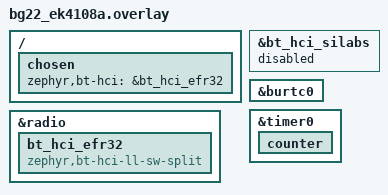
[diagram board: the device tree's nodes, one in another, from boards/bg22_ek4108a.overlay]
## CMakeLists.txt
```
cmake_minimum_required(VERSION 3.20.0)
# Compile test for modules/efr32-radio: Zephyr's own split controller on the EFR32BG22.
# UNVALIDATED ON HARDWARE; the radio hooks are stubs. Build with:
#   west build -b bg22_ek4108a tests/radio-port -- -DZEPHYR_EXTRA_MODULES=<repo>/modules/efr32-radio
if(NOT DEFINED ZEPHYR_RUST_MODULE)
  set(ZEPHYR_RUST_MODULE ${CMAKE_CURRENT_LIST_DIR}/../../vendor/zephyr-lang-rust)
endif()
list(APPEND ZEPHYR_EXTRA_MODULES
    ${CMAKE_CURRENT_LIST_DIR}/../../modules/efr32-radio
    ${ZEPHYR_RUST_MODULE})
find_package(Zephyr REQUIRED HINTS $ENV{ZEPHYR_BASE})
project(efr32_radio_port)
rust_cargo_application()
target_sources(app PRIVATE src/adv.c)
if(CONFIG_RADIO_PORT_GATT_TEST)
  target_sources(app PRIVATE src/gatt.c)
endif()
```

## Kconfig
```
# Test-only configuration for the EFR32 radio-port advertiser.

menu "EFR32 radio-port test"

config RADIO_PORT_GATT_TEST
	bool "Serve a read/write test characteristic to the QEMU Central"
	depends on BT_PERIPHERAL
	default n
	help
	  One 4-octet characteristic (src/gatt.c) that the QEMU connection
	  workload's Central writes and reads back to check the link end to
	  end. QEMU connection profile only.

config RADIO_PORT_PAIRING_TEST
	bool "Require LE Secure Connections pairing with a passkey for the test characteristic"
	depends on RADIO_PORT_GATT_TEST && BT_SMP && BT_APP_PASSKEY
	help
	  The characteristic needs an authenticated (MITM) encrypted link, as the product's do,
	  and the passkey is RADIO_PORT_PASSKEY through the app_passkey callback, as the
	  product's is (src/ble.rs). prj-pairing.conf.

config RADIO_PORT_ADV_CHANNEL_37_ONLY
	bool "Advertise on channel 37 only"
	help
	  For silicon connection tests while receive on channels 38 and 39
	  fails (docs/radio-tables.md 7.80): a Central's CONNECT_IND then
	  arrives on channel 37.

config RADIO_PORT_PASSKEY
	int "Fixed pairing passkey"
	depends on RADIO_PORT_PAIRING_TEST
	range 0 999999
	default 123456

endmenu

# Module defaults that must precede Zephyr's own (modules/efr32-radio/Kconfig.defaults).
osource "$(ZEPHYR_EFR32_RADIO_MODULE_DIR)/Kconfig.defaults"
source "Kconfig.zephyr"
```

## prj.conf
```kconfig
# Zephyr's own link layer, our lower layer. The Silicon Labs controller (BT_SILABS_EFR32) is off.
CONFIG_RUST=y
CONFIG_BT=y
CONFIG_BT_PERIPHERAL=y
CONFIG_BT_DEVICE_NAME="efr32-radio-port"
# The QEMU smoke must execute the real EFR32 HAL MMIO path.  The stub option
# remains useful for compile-only contract checks, but would make this smoke
# unable to say whether an accepted advertiser reached the radio model.
CONFIG_EFR32_RADIO_STUB_REGISTERS=n
# The silicon path: no QEMU-only seam. The sequencer answers a SCAN_REQ at T_IFS with the
# staged SCAN_RSP (docs/radio-tables.md 7.82, 7.87); the seams turned around in software after
# the completion, too late for a SCAN_REQ silicon would receive.
CONFIG_EFR32_RADIO_QEMU_TIFS=n
CONFIG_EFR32_RADIO_QEMU_RX_DESCRIPTOR=n
CONFIG_ENTROPY_GENERATOR=y
# System time and every kernel or radio wake-up come from the scheduler clock: BURTC
# across deep sleep, TIMER0 (HFXO) while the CPU runs.
CONFIG_CLOCK_EVENT_SYSTEM_TIMER=y
CONFIG_SILABS_BURTC_CLOCK_EVENT=y
CONFIG_COUNTER_SILABS_BURTC=n
CONFIG_COUNTER=y
CONFIG_COUNTER_SILABS_TIMER_CLOCK_EVENT=y
CONFIG_COUNTER_GECKO_STIMER=n
CONFIG_LOG=y
# A clock event delivered after its deadline (plus tolerance) is a fault in test builds.
# The lower link layer runs in meta-IRQ threads, not interrupts (modules/efr32-radio/hal/ll_threads.c):
# the LLL and radio jobs at the first priority, the ULL worker at the second.
CONFIG_NUM_METAIRQ_PRIORITIES=2
# This image runs in QEMU: its deadlines and budgets use the model's measured times
# (modules/efr32-radio/Kconfig, EFR32_RADIO_TIMING). The hardware profile selects silicon's.
CONFIG_EFR32_RADIO_TIMING_QEMU=y
# BT_CTLR_ZLI is only settable with the controller's advanced options visible.
CONFIG_BT_CTLR_ADVANCED_FEATURES=y
CONFIG_BT_CTLR_ZLI=n
# Interrupts only publish work now. One analyzer run peaked at 368 bytes, but
# nested interrupts with FP context overflowed 768.
CONFIG_ISR_STACK_SIZE=1024
# RAM for the lower-link-layer threads; the log buffer runs in overflow mode.
CONFIG_LOG_BUFFER_SIZE=256
# Stage 3 on silicon peaked at 1008 bytes on the main stack (CONFIG_INIT_STACKS high-water
# mark, 40 s with a host active scan); QEMU at 692.
CONFIG_MAIN_STACK_SIZE=1536
```

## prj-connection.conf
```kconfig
# Connection-role advertiser (Peripheral) profile for the QEMU connection e2e, merged with
# prj.conf using EXTRA_CONF_FILE. It runs the hardware configuration, the silicon path: both
# QEMU-only seams off, so the sequencer turns around at T_IFS and the HAL dates received frames
# from RAC.STIMER, which the Peripheral's anchor tracking needs (docs/radio-tables.md 7.79). The
# QEMU-configuration seams have no air time and their T_IFS starts at the LLL callback, so a
# connection on them cannot be spec-timed.
CONFIG_EFR32_RADIO_QEMU_TIFS=n
CONFIG_EFR32_RADIO_QEMU_RX_DESCRIPTOR=n
# The Central writes and reads back a test characteristic over the link (src/gatt.c).
CONFIG_RADIO_PORT_GATT_TEST=y
# A connection event runs paths advertising does not: lll_conn's callbacks in the completion job
# and its prepares in the LL threads. QEMU-test headroom only; the hardware profile keeps the
# measured values. The log buffer shrinks to fund them.
CONFIG_EFR32_RADIO_ULL_STACK_SIZE=896
CONFIG_EFR32_RADIO_LAUNCH_STACK_SIZE=640
CONFIG_EFR32_RADIO_COMPLETION_STACK_SIZE=960
CONFIG_LOG_BUFFER_SIZE=256
# In QEMU the M33 runs lll_conn_isr_rx's path to RESPOND in 133 us, past the ~107 us the
# sequencer's T_IFS hold leaves after a frame's end, and lll_conn_isr_tx's path to PENDING in
# 99 us against ~5 us of slack after one 72 us interrupt (docs/radio-tables.md 7.79): every
# connection-event turnaround misses its spec-derived start-by in the model. This QEMU-only
# profile therefore counts missed deadlines instead of shutting the radio down; the advertising
# profiles and every hardware image keep the safe-shutdown policy.
CONFIG_SCHED_DEADLINE_MISS_COUNT=y
```

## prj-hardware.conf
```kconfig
# The synthetic QEMU receive and TIFS seams do not describe silicon.
CONFIG_EFR32_RADIO_QEMU_TIFS=n
CONFIG_EFR32_RADIO_QEMU_RX_DESCRIPTOR=n

# Preserve the complete first-fault report on the small-RAM hardware smoke.
CONFIG_LOG_MODE_IMMEDIATE=y

# The one-shot bring-up checkpoints print synchronously (immediate logging)
# from the lower link layer's release paths, ticker compare and doorbell
# interrupts included: the first ticker run then starts 4.4 ms after its
# compare, a missed deadline that shuts the radio down. Stage 3 is on air.
CONFIG_EFR32_RADIO_BRINGUP_TRACE=n
# Immediate formatting of fault reports runs on the LL contexts. With the LLL
# prepares in the LLL context (CONFIG_BT_CTLR_LLL_PRIO above CONFIG_BT_CTLR_ULL_HIGH_PRIO),
# stage 3 on silicon peaked at 820 bytes in the LLL context and 796 in the ULL
# worker (CONFIG_INIT_STACKS high-water marks, 40 s with a host active scan);
# 960 each covers those plus FP exception entry (104 bytes; 136 in the worker).
CONFIG_EFR32_RADIO_ULL_STACK_SIZE=960
CONFIG_EFR32_RADIO_LLL_STACK_SIZE=960
# Missed-deadline reports list the last four job starts (RAM).
CONFIG_SCHED_DEADLINE_MISS_HISTORY=4
# Budgets, paths and the interrupt allowance behind every deadline: the silicon measurements.
CONFIG_EFR32_RADIO_TIMING_SILICON=y

# No libc heap. The host's PSA ECB and CMAC once allocated their contexts from it; they run
# on RADIOAES since docs/radio-tables.md 7.81 (crypto/radioaes_psa.c), and the linker now
# discards malloc, calloc and free from every radio-port image (zephyr.map). The 3504-octet
# arena this profile kept was unreferenced RAM, and the pairing profile (prj-pairing.conf)
# needs it: with it the silicon pairing image overflowed RAM by 3092 octets (7.84).
CONFIG_COMMON_LIBC_MALLOC_ARENA_SIZE=0
```

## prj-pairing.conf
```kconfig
# Pairing profile, merged after prj-connection.conf: the product's security (prj.conf at the
# repository root): LE Secure Connections only, MITM enforced, passkey from the application. The
# test characteristic then needs an authenticated encrypted link (src/gatt.c), so every GATT round
# of the Central runs over link-layer AES-CCM (RADIOAES, modules/efr32-radio/crypto).
CONFIG_BT_SMP=y
CONFIG_BT_SMP_SC_PAIR_ONLY=y
CONFIG_BT_SMP_ENFORCE_MITM=y
CONFIG_BT_APP_PASSKEY=y
CONFIG_RADIO_PORT_PAIRING_TEST=y
# As the product (prj.conf): no controller privacy or filter accept list (BT_SMP otherwise
# defaults BT_CTLR_PRIVACY on) and no GATT caching. With controller privacy the sequencer
# cannot stage the scan response (lll/lll_adv_stage.c needs no resolving list), so the M33
# decides each SCAN_REQ at its end; on silicon admission found that turnaround unsat at the
# laptop's first SCAN_REQ (55.6 us window, 58.1 us interrupt allowance) and shut the radio
# down (docs/radio-tables.md 7.84). GATT caching's database hash needs multi-part PSA CMAC,
# which crypto/radioaes_psa.c does not offer ("CMAC operation init failed -134").
CONFIG_BT_CTLR_PRIVACY=n
CONFIG_BT_CTLR_FILTER_ACCEPT_LIST=n
CONFIG_BT_GATT_CACHING=n
```

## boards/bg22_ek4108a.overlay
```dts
/*
 * Zephyr's software link layer instead of the Silicon Labs binary controller.
 * UNVALIDATED ON HARDWARE.
 */
&bt_hci_silabs {
	status = "disabled";
};

&radio {
	bt_hci_efr32: bt_hci_efr32 {
		compatible = "zephyr,bt-hci-ll-sw-split";
		status = "okay";
	};
};

/ {
	chosen {
		zephyr,bt-hci = &bt_hci_efr32;
	};
};

&burtc0 {
	status = "okay";
};

/* HFXO-clocked 32-bit TIMER0: the scheduler clock's active-state provider. */
&timer0 {
	status = "okay";

	counter {
		status = "okay";
	};
};
```

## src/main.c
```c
#include <zephyr/kernel.h>
#include <zephyr/bluetooth/bluetooth.h>

int main(void)
{
	int err = bt_enable(NULL);

	printk("bt_enable: %d\n", err);
	return 0;
}
```

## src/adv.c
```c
/*
 * Advertising options that depend on the build configuration, for src/lib.rs.
 * SPDX-License-Identifier: Apache-2.0
 */
#include <stdint.h>
#include <zephyr/bluetooth/bluetooth.h>

uint32_t radio_port_adv_channels_disabled(void)
{
	return IS_ENABLED(CONFIG_RADIO_PORT_ADV_CHANNEL_37_ONLY) ?
	       (BT_LE_ADV_OPT_DISABLE_CHAN_38 | BT_LE_ADV_OPT_DISABLE_CHAN_39) : 0U;
}
```

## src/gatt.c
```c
/*
 * Test GATT service of the connection profile: one 4-octet characteristic the Central writes
 * and reads back over the link (tests/radio-rx-port/src/central.c in QEMU, a host Central on
 * silicon).
 * With RADIO_PORT_PAIRING_TEST it needs an authenticated encrypted link, as the product's
 * characteristics do, and the passkey comes from the app_passkey callback, as the product's
 * does (src/ble.rs).
 * SPDX-License-Identifier: Apache-2.0
 */
#include <zephyr/kernel.h>
#include <zephyr/init.h>
#include <zephyr/sys/printk.h>
#include <zephyr/bluetooth/conn.h>
#include <zephyr/bluetooth/gatt.h>
#include <zephyr/bluetooth/uuid.h>
#include <zephyr/sys/printk.h>

/* Random 128-bit UUIDs owned by this test. */
#define RADIO_PORT_SVC_UUID BT_UUID_128_ENCODE(0x5b2a1c00, 0x6f3e, 0x4c1d, 0x9a7b, 0x0e1f2d3c4b5a)
#define RADIO_PORT_CHR_UUID BT_UUID_128_ENCODE(0x5b2a1c01, 0x6f3e, 0x4c1d, 0x9a7b, 0x0e1f2d3c4b5a)

#if defined(CONFIG_RADIO_PORT_PAIRING_TEST)
#define RADIO_PORT_PERM (BT_GATT_PERM_READ_AUTHEN | BT_GATT_PERM_WRITE_AUTHEN)
#else
#define RADIO_PORT_PERM (BT_GATT_PERM_READ | BT_GATT_PERM_WRITE)
#endif

static uint8_t value[4];

static ssize_t value_read(struct bt_conn *conn, const struct bt_gatt_attr *attr, void *buf,
			  uint16_t len, uint16_t offset)
{
	return bt_gatt_attr_read(conn, attr, buf, len, offset, value, sizeof(value));
}

static ssize_t value_write(struct bt_conn *conn, const struct bt_gatt_attr *attr,
			   const void *buf, uint16_t len, uint16_t offset, uint8_t flags)
{
	ARG_UNUSED(conn);
	ARG_UNUSED(attr);
	ARG_UNUSED(flags);
	if (offset != 0U || len != sizeof(value)) {
		return BT_GATT_ERR(BT_ATT_ERR_INVALID_ATTRIBUTE_LEN);
	}
	memcpy(value, buf, sizeof(value));
	return len;
}

BT_GATT_SERVICE_DEFINE(radio_port_svc,
	BT_GATT_PRIMARY_SERVICE(BT_UUID_DECLARE_128(RADIO_PORT_SVC_UUID)),
	BT_GATT_CHARACTERISTIC(BT_UUID_DECLARE_128(RADIO_PORT_CHR_UUID),
			       BT_GATT_CHRC_READ | BT_GATT_CHRC_WRITE,
			       RADIO_PORT_PERM, value_read, value_write, NULL));

/* Link events on the console, for a hardware run against a host Central. */
static void radio_port_connected(struct bt_conn *conn, uint8_t err)
{
	ARG_UNUSED(conn);
	printk("peripheral_connected: %u\n", err);
}

static void radio_port_disconnected(struct bt_conn *conn, uint8_t reason)
{
	ARG_UNUSED(conn);
	printk("peripheral_disconnected: 0x%02x\n", reason);
}

BT_CONN_CB_DEFINE(radio_port_conn_cb) = {
	.connected = radio_port_connected,
	.disconnected = radio_port_disconnected,
};

#if defined(CONFIG_RADIO_PORT_PAIRING_TEST)
/* DisplayOnly through app_passkey (subsys/bluetooth/host/smp.c get_io_capa()), so a keyboard
 * Central gets authenticated passkey entry.
 */
static uint32_t app_passkey(struct bt_conn *conn)
{
	ARG_UNUSED(conn);
	return CONFIG_RADIO_PORT_PASSKEY;
}

static void pairing_complete(struct bt_conn *conn, bool bonded)
{
	ARG_UNUSED(conn);
	printk("peripheral_paired: bonded %d\n", bonded);
}

static void pairing_failed(struct bt_conn *conn, enum bt_security_err reason)
{
	ARG_UNUSED(conn);
	printk("peripheral_pairing_failed: %d\n", reason);
}

static const struct bt_conn_auth_cb auth_cb = {
	.app_passkey = app_passkey,
};

static struct bt_conn_auth_info_cb auth_info_cb = {
	.pairing_complete = pairing_complete,
	.pairing_failed = pairing_failed,
};

static int radio_port_pairing_init(void)
{
	int err = bt_conn_auth_cb_register(&auth_cb);

	if (err == 0) {
		err = bt_conn_auth_info_cb_register(&auth_info_cb);
	}
	return err;
}

SYS_INIT(radio_port_pairing_init, APPLICATION, 0);
#endif /* CONFIG_RADIO_PORT_PAIRING_TEST */
```
